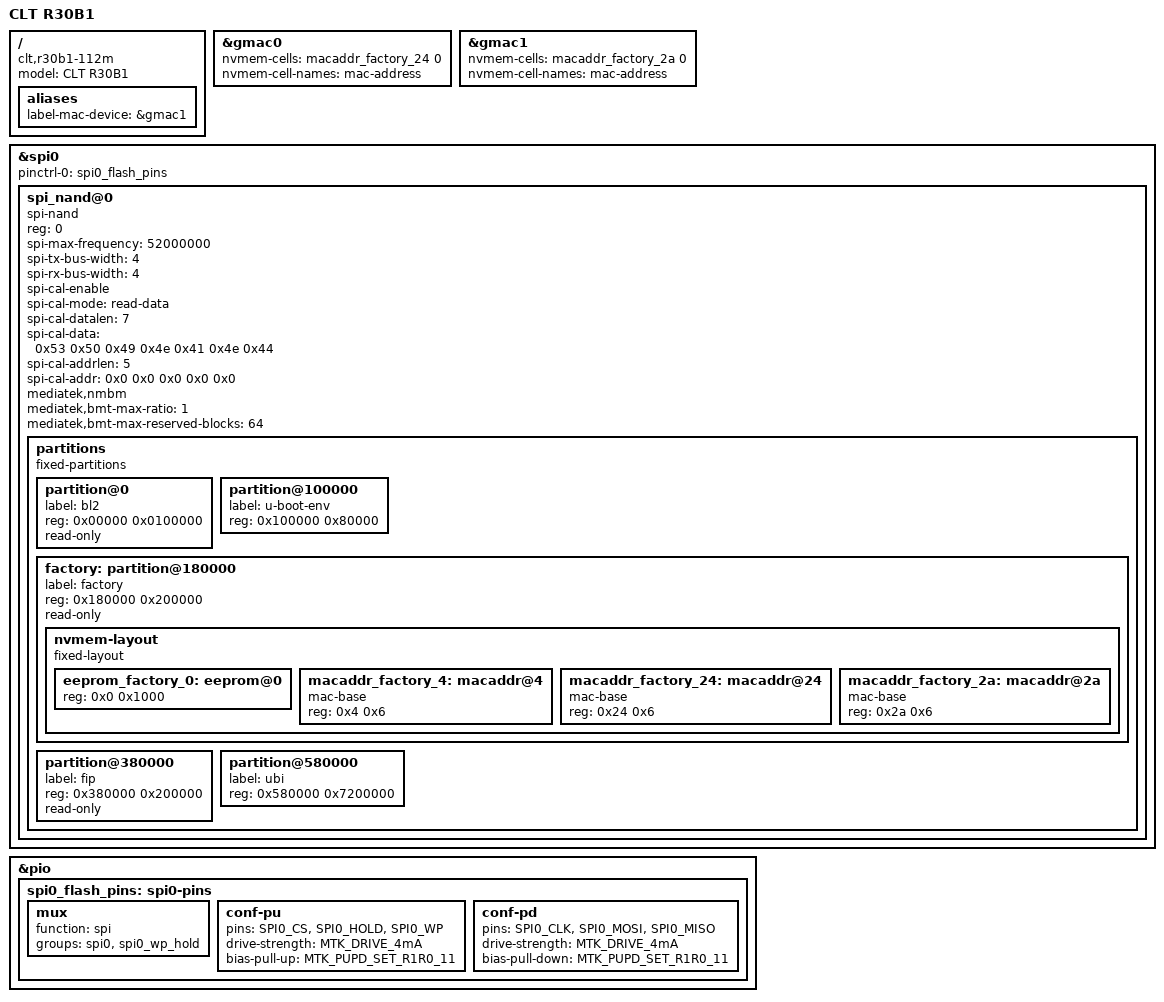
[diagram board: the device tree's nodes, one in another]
// SPDX-License-Identifier: GPL-2.0-or-later OR MIT

/dts-v1/;
#include "mt7981b-clt-r30b1.dts"

/ {
	model = "CLT R30B1";
	compatible = "clt,r30b1-112m", "mediatek,mt7981";

	aliases {
		label-mac-device = &gmac1;
	};
};

&gmac0 {
	nvmem-cells = <&macaddr_factory_24 0>;
	nvmem-cell-names = "mac-address";
};

&gmac1 {
	nvmem-cells = <&macaddr_factory_2a 0>;
	nvmem-cell-names = "mac-address";
};

&spi0 {
	pinctrl-names = "default";
	pinctrl-0 = <&spi0_flash_pins>;
	status = "okay";

	spi_nand@0 {
		compatible = "spi-nand";
		reg = <0>;

		spi-max-frequency = <52000000>;
		spi-tx-bus-width = <4>;
		spi-rx-bus-width = <4>;

		spi-cal-enable;
		spi-cal-mode = "read-data";
		spi-cal-datalen = <7>;
		spi-cal-data = /bits/ 8 <0x53 0x50 0x49 0x4e 0x41 0x4e 0x44>;
		spi-cal-addrlen = <5>;
		spi-cal-addr = /bits/ 32 <0x0 0x0 0x0 0x0 0x0>;

		mediatek,nmbm;
		mediatek,bmt-max-ratio = <1>;
		mediatek,bmt-max-reserved-blocks = <64>;

		partitions {
			compatible = "fixed-partitions";
			#address-cells = <1>;
			#size-cells = <1>;

			partition@0 {
				label = "bl2";
				reg = <0x00000 0x0100000>;
				read-only;
			};

			partition@100000 {
				label = "u-boot-env";
				reg = <0x100000 0x80000>;
			};

			factory: partition@180000 {
				label = "factory";
				reg = <0x180000 0x200000>;
				read-only;

				nvmem-layout {
					compatible = "fixed-layout";
					#address-cells = <1>;
					#size-cells = <1>;

					eeprom_factory_0: eeprom@0 {
						reg = <0x0 0x1000>;
					};

					macaddr_factory_4: macaddr@4 {
						compatible = "mac-base";
						reg = <0x4 0x6>;
						#nvmem-cell-cells = <1>;
					};

					macaddr_factory_24: macaddr@24 {
						compatible = "mac-base";
						reg = <0x24 0x6>;
						#nvmem-cell-cells = <1>;
					};

					macaddr_factory_2a: macaddr@2a {
						compatible = "mac-base";
						reg = <0x2a 0x6>;
						#nvmem-cell-cells = <1>;
					};
				};
			};

			partition@380000 {
				label = "fip";
				reg = <0x380000 0x200000>;
				read-only;
			};

			partition@580000 {
				label = "ubi";
				reg = <0x580000 0x7200000>;
			};
		};
	};
};

&pio {
	spi0_flash_pins: spi0-pins {
		mux {
			function = "spi";
			groups = "spi0", "spi0_wp_hold";
		};

		conf-pu {
			pins = "SPI0_CS", "SPI0_HOLD", "SPI0_WP";
			drive-strength = <MTK_DRIVE_4mA>;
			bias-pull-up = <MTK_PUPD_SET_R1R0_11>;
		};

		conf-pd {
			pins = "SPI0_CLK", "SPI0_MOSI", "SPI0_MISO";
			drive-strength = <MTK_DRIVE_4mA>;
			bias-pull-down = <MTK_PUPD_SET_R1R0_11>;
		};
	};
};
